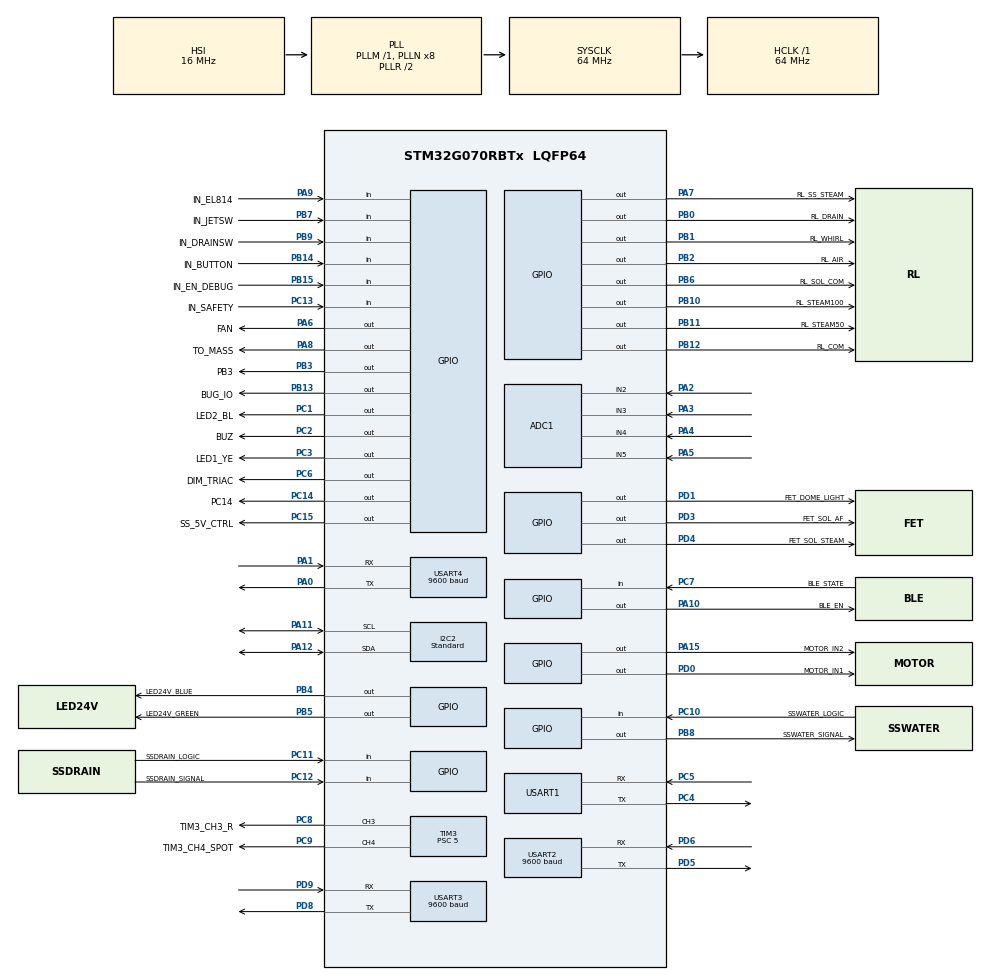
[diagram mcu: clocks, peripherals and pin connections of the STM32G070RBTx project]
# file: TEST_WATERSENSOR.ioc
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ADC1.Channel-0\#ChannelRegularConversion=ADC_CHANNEL_2
ADC1.Channel-1\#ChannelRegularConversion=ADC_CHANNEL_3
ADC1.Channel-2\#ChannelRegularConversion=ADC_CHANNEL_4
ADC1.Channel-3\#ChannelRegularConversion=ADC_CHANNEL_5
ADC1.ClockPrescaler=ADC_CLOCK_ASYNC_DIV4
ADC1.ContinuousConvMode=ENABLE
ADC1.DMAContinuousRequests=ENABLE
ADC1.NbrOfConversion=4
ADC1.NbrOfConversionFlag=1
ADC1.Rank-0\#ChannelRegularConversion=1
ADC1.Rank-1\#ChannelRegularConversion=2
ADC1.Rank-2\#ChannelRegularConversion=3
ADC1.Rank-3\#ChannelRegularConversion=4
ADC1.SamplingTime-0\#ChannelRegularConversion=ADC_SAMPLINGTIME_COMMON_1
ADC1.SamplingTime-1\#ChannelRegularConversion=ADC_SAMPLINGTIME_COMMON_1
ADC1.SamplingTime-2\#ChannelRegularConversion=ADC_SAMPLINGTIME_COMMON_1
ADC1.SamplingTime-3\#ChannelRegularConversion=ADC_SAMPLINGTIME_COMMON_1
ADC1.SamplingTimeCommon1=ADC_SAMPLETIME_160CYCLES_5
ADC1.SamplingTimeCommon2=ADC_SAMPLETIME_160CYCLES_5
ADC1.SelectedChannel=ADC_CHANNEL_2|ADC_CHANNEL_3|ADC_CHANNEL_4|ADC_CHANNEL_5
ADC1.master=1
Dma.ADC1.0.Direction=DMA_PERIPH_TO_MEMORY
Dma.ADC1.0.EventEnable=DISABLE
Dma.ADC1.0.Instance=DMA1_Channel1
Dma.ADC1.0.MemDataAlignment=DMA_MDATAALIGN_HALFWORD
Dma.ADC1.0.MemInc=DMA_MINC_ENABLE
Dma.ADC1.0.Mode=DMA_CIRCULAR
Dma.ADC1.0.PeriphDataAlignment=DMA_PDATAALIGN_HALFWORD
Dma.ADC1.0.PeriphInc=DMA_PINC_DISABLE
Dma.ADC1.0.Polarity=HAL_DMAMUX_REQ_GEN_RISING
Dma.ADC1.0.Priority=DMA_PRIORITY_LOW
Dma.ADC1.0.RequestNumber=1
Dma.ADC1.0.SignalID=NONE
Dma.ADC1.0.SyncEnable=DISABLE
Dma.ADC1.0.SyncPolarity=HAL_DMAMUX_SYNC_NO_EVENT
Dma.ADC1.0.SyncRequestNumber=1
Dma.ADC1.0.SyncSignalID=NONE
Dma.Request0=ADC1
I2C2.I2C_Speed_Mode=I2C_Standard
I2C2.Timing=0x10707DBC
IWDG.Prescaler=IWDG_PRESCALER_32
Mcu.Family=STM32G0
Mcu.Name=STM32G070RBTx
Mcu.Package=LQFP64
NVIC.ADC1_IRQn=true\:0\:0\:true\:false\:true\:true\:true\:true
NVIC.DMA1_Channel1_IRQn=true\:0\:0\:true\:false\:true\:false\:true\:true
NVIC.TIM6_IRQn=true\:1\:0\:true\:false\:true\:true\:true\:true
NVIC.TIM7_IRQn=true\:0\:0\:false\:false\:true\:true\:true\:true
NVIC.USART1_IRQn=true\:0\:0\:false\:false\:true\:true\:true\:true
NVIC.USART2_IRQn=true\:0\:0\:false\:false\:true\:true\:true\:true
NVIC.USART3_4_IRQn=true\:0\:0\:false\:false\:true\:true\:true\:true
PA0.Mode=Asynchronous
PA0.Signal=USART4_TX
PA1.Mode=Asynchronous
PA1.Signal=USART4_RX
PA10.GPIO_Label=BLE_EN
PA10.GPIO_PuPd=GPIO_PULLDOWN
PA10.Signal=GPIO_Output
PA11\ [PA9].GPIO_Pu=GPIO_PULLUP
PA11\ [PA9].Mode=I2C
PA11\ [PA9].Signal=I2C2_SCL
PA12\ [PA10].GPIO_Pu=GPIO_PULLUP
PA12\ [PA10].Mode=I2C
PA12\ [PA10].Signal=I2C2_SDA
PA13.Mode=Serial_Wire
PA13.Signal=SYS_SWDIO
PA14-BOOT0.Mode=Serial_Wire
PA14-BOOT0.Signal=SYS_SWCLK
PA15.GPIO_Label=MOTOR_IN2
PA15.Signal=GPIO_Output
PA2.Mode=IN2
PA2.Signal=ADC1_IN2
PA3.Mode=IN3
PA3.Signal=ADC1_IN3
PA4.Mode=IN4
PA4.Signal=ADC1_IN4
PA5.Mode=IN5
PA5.Signal=ADC1_IN5
PA6.GPIO_Label=FAN
PA6.GPIO_ModeDefaultOutputPP=GPIO_MODE_OUTPUT_PP
PA6.GPIO_PuPd=GPIO_PULLDOWN
PA6.PinState=GPIO_PIN_RESET
PA6.Signal=GPIO_Output
PA7.GPIO_Label=RL_SS_STEAM
PA7.GPIO_ModeDefaultOutputPP=GPIO_MODE_OUTPUT_PP
PA7.GPIO_PuPd=GPIO_PULLDOWN
PA7.GPIO_Speed=GPIO_SPEED_FREQ_LOW
PA7.PinState=GPIO_PIN_RESET
PA7.Signal=GPIO_Output
PA8.GPIO_Label=TO_MASS
PA8.GPIO_PuPd=GPIO_PULLDOWN
PA8.GPIO_Speed=GPIO_SPEED_FREQ_LOW
PA8.Signal=GPIO_Output
PA9.GPIO_Label=IN_EL814
PA9.GPIO_PuPd=GPIO_PULLUP
PA9.Signal=GPIO_Input
PB0.GPIO_Label=RL_DRAIN
PB0.GPIO_ModeDefaultOutputPP=GPIO_MODE_OUTPUT_PP
PB0.GPIO_PuPd=GPIO_PULLDOWN
PB0.GPIO_Speed=GPIO_SPEED_FREQ_LOW
PB0.PinState=GPIO_PIN_RESET
PB0.Signal=GPIO_Output
PB1.GPIO_Label=RL_WHIRL
PB1.GPIO_ModeDefaultOutputPP=GPIO_MODE_OUTPUT_PP
PB1.GPIO_PuPd=GPIO_PULLDOWN
PB1.GPIO_Speed=GPIO_SPEED_FREQ_LOW
PB1.PinState=GPIO_PIN_RESET
PB1.Signal=GPIO_Output
PB10.GPIO_Label=RL_STEAM100
PB10.GPIO_ModeDefaultOutputPP=GPIO_MODE_OUTPUT_PP
PB10.GPIO_PuPd=GPIO_PULLDOWN
PB10.GPIO_Speed=GPIO_SPEED_FREQ_LOW
PB10.PinState=GPIO_PIN_RESET
PB10.Signal=GPIO_Output
PB11.GPIO_Label=RL_STEAM50
PB11.GPIO_ModeDefaultOutputPP=GPIO_MODE_OUTPUT_PP
PB11.GPIO_PuPd=GPIO_PULLDOWN
PB11.GPIO_Speed=GPIO_SPEED_FREQ_LOW
PB11.PinState=GPIO_PIN_RESET
PB11.Signal=GPIO_Output
PB12.GPIO_Label=RL_COM
PB12.GPIO_ModeDefaultOutputPP=GPIO_MODE_OUTPUT_PP
PB12.GPIO_PuPd=GPIO_PULLDOWN
PB12.GPIO_Speed=GPIO_SPEED_FREQ_LOW
PB12.PinState=GPIO_PIN_RESET
PB12.Signal=GPIO_Output
PB13.GPIO_Label=BUG_IO
PB13.GPIO_ModeDefaultOutputPP=GPIO_MODE_OUTPUT_PP
PB13.GPIO_PuPd=GPIO_PULLUP
PB13.GPIO_Speed=GPIO_SPEED_FREQ_VERY_HIGH
PB13.PinState=GPIO_PIN_RESET
PB13.Signal=GPIO_Output
PB14.GPIO_Label=IN_BUTTON
PB14.GPIO_Mode=GPIO_MODE_INPUT
PB14.GPIO_PuPd=GPIO_PULLUP
PB14.Signal=GPIO_Input
PB15.GPIO_Label=IN_EN_DEBUG
PB15.GPIO_Mode=GPIO_MODE_INPUT
PB15.GPIO_PuPd=GPIO_PULLUP
PB15.Signal=GPIO_Input
PB2.GPIO_Label=RL_AIR
PB2.GPIO_ModeDefaultOutputPP=GPIO_MODE_OUTPUT_PP
PB2.GPIO_PuPd=GPIO_PULLDOWN
PB2.GPIO_Speed=GPIO_SPEED_FREQ_LOW
PB2.PinState=GPIO_PIN_RESET
PB2.Signal=GPIO_Output
PB3.GPIO_Label=PB3
PB3.Signal=GPIO_Output
PB4.GPIO_Label=LED24V_BLUE
PB4.GPIO_ModeDefaultOutputPP=GPIO_MODE_OUTPUT_PP
PB4.GPIO_PuPd=GPIO_PULLUP
PB4.PinState=GPIO_PIN_SET
PB4.Signal=GPIO_Output
PB5.GPIO_Label=LED24V_GREEN
PB5.GPIO_ModeDefaultOutputPP=GPIO_MODE_OUTPUT_PP
PB5.GPIO_PuPd=GPIO_PULLUP
PB5.PinState=GPIO_PIN_SET
PB5.Signal=GPIO_Output
PB6.GPIO_Label=RL_SOL_COM
PB6.GPIO_ModeDefaultOutputPP=GPIO_MODE_OUTPUT_PP
PB6.GPIO_PuPd=GPIO_PULLDOWN
PB6.GPIO_Speed=GPIO_SPEED_FREQ_LOW
PB6.PinState=GPIO_PIN_RESET
PB6.Signal=GPIO_Output
PB7.GPIO_Label=IN_JETSW
PB7.GPIO_Mode=GPIO_MODE_INPUT
PB7.GPIO_PuPd=GPIO_PULLUP
PB7.Signal=GPIO_Input
PB8.GPIO_Label=SSWATER_SIGNAL
PB8.GPIO_ModeDefaultOutputPP=GPIO_MODE_OUTPUT_PP
PB8.GPIO_PuPd=GPIO_PULLUP
PB8.PinState=GPIO_PIN_SET
PB8.Signal=GPIO_Output
PB9.GPIO_Label=IN_DRAINSW
PB9.GPIO_Mode=GPIO_MODE_INPUT
PB9.GPIO_PuPd=GPIO_PULLUP
PB9.Signal=GPIO_Input
PC1.GPIO_Label=LED2_BL
PC1.Signal=GPIO_Output
PC10.GPIO_Label=SSWATER_LOGIC
PC10.GPIO_Mode=GPIO_MODE_INPUT
PC10.GPIO_PuPd=GPIO_PULLUP
PC10.Signal=GPIO_Input
PC11.GPIO_Label=SSDRAIN_LOGIC
PC11.GPIO_Mode=GPIO_MODE_INPUT
PC11.GPIO_PuPd=GPIO_PULLUP
PC11.Signal=GPIO_Input
PC12.GPIO_Label=SSDRAIN_SIGNAL
PC12.GPIO_PuPd=GPIO_PULLUP
PC12.Signal=GPIO_Input
PC13.GPIO_Label=IN_SAFETY
PC13.GPIO_Mode=GPIO_MODE_INPUT
PC13.GPIO_PuPd=GPIO_PULLUP
PC13.Signal=GPIO_Input
PC14-OSC32_IN\ (PC14).GPIO_Label=PC14
PC14-OSC32_IN\ (PC14).Signal=GPIO_Output
PC15-OSC32_OUT\ (PC15).GPIO_Label=SS_5V_CTRL
PC15-OSC32_OUT\ (PC15).GPIO_ModeDefaultOutputPP=GPIO_MODE_OUTPUT_PP
PC15-OSC32_OUT\ (PC15).GPIO_PuPd=GPIO_PULLUP
PC15-OSC32_OUT\ (PC15).PinState=GPIO_PIN_SET
PC15-OSC32_OUT\ (PC15).Signal=GPIO_Output
PC2.GPIO_Label=BUZ
PC2.GPIO_PuPd=GPIO_PULLDOWN
PC2.Signal=GPIO_Output
PC3.GPIO_Label=LED1_YE
PC3.GPIO_PuPd=GPIO_NOPULL
PC3.Signal=GPIO_Output
PC4.Mode=Asynchronous
PC4.Signal=USART1_TX
PC5.Mode=Asynchronous
PC5.Signal=USART1_RX
PC6.GPIO_Label=DIM_TRIAC
PC6.GPIO_ModeDefaultOutputPP=GPIO_MODE_OUTPUT_PP
PC6.GPIO_PuPd=GPIO_PULLDOWN
PC6.GPIO_Speed=GPIO_SPEED_FREQ_HIGH
PC6.Signal=GPIO_Output
PC7.GPIO_Label=BLE_STATE
PC7.GPIO_PuPd=GPIO_PULLUP
PC7.Signal=GPIO_Input
PC8.GPIO_Label=TIM3_CH3_R
PC8.Signal=S_TIM3_CH3
PC9.GPIO_Label=TIM3_CH4_SPOT
PC9.Signal=S_TIM3_CH4
PD0.GPIO_Label=MOTOR_IN1
PD0.Signal=GPIO_Output
PD1.GPIO_Label=FET_DOME_LIGHT
PD1.GPIO_ModeDefaultOutputPP=GPIO_MODE_OUTPUT_PP
PD1.GPIO_PuPd=GPIO_PULLUP
PD1.GPIO_Speed=GPIO_SPEED_FREQ_LOW
PD1.PinState=GPIO_PIN_SET
PD1.Signal=GPIO_Output
PD3.GPIO_Label=FET_SOL_AF
PD3.GPIO_ModeDefaultOutputPP=GPIO_MODE_OUTPUT_PP
PD3.GPIO_PuPd=GPIO_PULLUP
PD3.GPIO_Speed=GPIO_SPEED_FREQ_LOW
PD3.PinState=GPIO_PIN_SET
PD3.Signal=GPIO_Output
PD4.GPIO_Label=FET_SOL_STEAM
PD4.GPIO_ModeDefaultOutputPP=GPIO_MODE_OUTPUT_PP
PD4.GPIO_PuPd=GPIO_PULLUP
PD4.GPIO_Speed=GPIO_SPEED_FREQ_LOW
PD4.PinState=GPIO_PIN_SET
PD4.Signal=GPIO_Output
PD5.Mode=Asynchronous
PD5.Signal=USART2_TX
PD6.Mode=Asynchronous
PD6.Signal=USART2_RX
PD8.Mode=Asynchronous
PD8.Signal=USART3_TX
PD9.Mode=Asynchronous
PD9.Signal=USART3_RX
ProjectManager.HeapSize=0x200
ProjectManager.StackSize=0x400
ProjectManager.TargetToolchain=STM32CubeIDE
RCC.ADCFreq_Value=64000000
RCC.AHBFreq_Value=64000000
RCC.CortexFreq_Value=64000000
RCC.EXTERNAL_CLOCK_VALUE=48000
RCC.HCLKFreq_Value=64000000
RCC.HSE_VALUE=8000000
RCC.HSI_VALUE=16000000
RCC.LSE_VALUE=32768
RCC.SYSCLKFreq_VALUE=64000000
RCC.SYSCLKSource=RCC_SYSCLKSOURCE_PLLCLK
RCC.VCOOutputFreq_Value=128000000
SH.S_TIM3_CH3.0=TIM3_CH3,PWM Generation3 CH3
SH.S_TIM3_CH4.0=TIM3_CH4,PWM Generation4 CH4
TIM3.AutoReloadPreload=TIM_AUTORELOAD_PRELOAD_ENABLE
TIM3.Channel-PWM\ Generation3\ CH3=TIM_CHANNEL_3
TIM3.Channel-PWM\ Generation4\ CH4=TIM_CHANNEL_4
TIM3.OC3Preload_PWM=DISABLE
TIM3.OCFastMode_PWM-PWM\ Generation3\ CH3=TIM_OCFAST_ENABLE
TIM3.OCPolarity_3=TIM_OCPOLARITY_LOW
TIM3.OCPolarity_4=TIM_OCPOLARITY_LOW
TIM3.Period=38000
TIM3.Prescaler=5
TIM3.Pulse-PWM\ Generation3\ CH3=0
TIM6.Period=104
TIM6.Prescaler=64
TIM7.AutoReloadPreload=TIM_AUTORELOAD_PRELOAD_ENABLE
TIM7.Period=999
TIM7.Prescaler=64
USART1.VirtualMode-Asynchronous=VM_ASYNC
USART2.BaudRate=9600
USART2.VirtualMode-Asynchronous=VM_ASYNC
USART3.BaudRate=9600
USART3.OneBitSampling=UART_ONE_BIT_SAMPLE_DISABLE
USART3.VirtualMode-Asynchronous=VM_ASYNC
USART4.BaudRate=9600
USART4.VirtualMode-Asynchronous=VM_ASYNC
VP_IWDG_VS_IWDG.Mode=IWDG_Activate
VP_SYS_VS_DBSignals.Mode=DisableDeadBatterySignals
VP_TIM3_VS_ClockSourceINT.Mode=Internal
VP_TIM6_VS_ClockSourceINT.Mode=Enable_Timer
VP_TIM7_VS_ClockSourceINT.Mode=Enable_Timer
board=custom

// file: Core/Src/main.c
/* USER CODE BEGIN Header */
/**
  ******************************************************************************
  * @file           : main.c
  * @brief          : Main program body
  ******************************************************************************
  * @attention
  *
  * Copyright (c) 2023 STMicroelectronics.
  * All rights reserved.
  *
  * This software is licensed under terms that can be found in the LICENSE file
  * in the root directory of this software component.
  * If no LICENSE file comes with this software, it is provided AS-IS.
  *
  ******************************************************************************
  */
/* USER CODE END Header */
#include "main.h"

/* USER CODE BEGIN Includes */
#include "myHeader.h"
/* USER CODE END Includes */

ADC_HandleTypeDef hadc1;
DMA_HandleTypeDef hdma_adc1;

I2C_HandleTypeDef hi2c2;

IWDG_HandleTypeDef hiwdg;

TIM_HandleTypeDef htim3;
TIM_HandleTypeDef htim6;
TIM_HandleTypeDef htim7;

UART_HandleTypeDef huart1;
UART_HandleTypeDef huart2;
UART_HandleTypeDef huart3;
UART_HandleTypeDef huart4;

void SystemClock_Config(void);
static void MX_GPIO_Init(void);
static void MX_DMA_Init(void);
static void MX_ADC1_Init(void);
static void MX_TIM3_Init(void);
static void MX_TIM6_Init(void);
static void MX_USART2_UART_Init(void);
static void MX_USART3_UART_Init(void);
static void MX_USART4_UART_Init(void);
static void MX_IWDG_Init(void);
static void MX_USART1_UART_Init(void);
static void MX_I2C2_Init(void);
static void MX_TIM7_Init(void);

int main(void)
{

  /* MCU Configuration--------------------------------------------------------*/

  /* Reset of all peripherals, Initializes the Flash interface and the Systick. */
  HAL_Init();

  /* Configure the system clock */
  SystemClock_Config();

  /* Initialize all configured peripherals */
  MX_GPIO_Init();
  MX_DMA_Init();
  MX_ADC1_Init();
  MX_TIM3_Init();
  MX_TIM6_Init();
  MX_USART2_UART_Init();
  MX_USART3_UART_Init();
  MX_USART4_UART_Init();
  MX_IWDG_Init();
  MX_USART1_UART_Init();
  MX_I2C2_Init();
  MX_TIM7_Init();
  /* USER CODE BEGIN 2 */

  testWaterSensorInit();

  /* USER CODE END 2 */

  /* Infinite loop */
  /* USER CODE BEGIN WHILE */
  HAL_IWDG_Init(&hiwdg);
  while (1)
  {
      HAL_IWDG_Refresh(&hiwdg);
    /* USER CODE END WHILE */

    /* USER CODE BEGIN 3 */
      testWaterSensorLoop();
  }
  /* USER CODE END 3 */
}

void SystemClock_Config(void)
{
  RCC_OscInitTypeDef RCC_OscInitStruct = {0};
  RCC_ClkInitTypeDef RCC_ClkInitStruct = {0};

  /** Configure the main internal regulator output voltage
  */
  HAL_PWREx_ControlVoltageScaling(PWR_REGULATOR_VOLTAGE_SCALE1);

  /** Initializes the RCC Oscillators according to the specified parameters
  * in the RCC_OscInitTypeDef structure.
  */
  RCC_OscInitStruct.OscillatorType = RCC_OSCILLATORTYPE_HSI|RCC_OSCILLATORTYPE_LSI;
  RCC_OscInitStruct.HSIState = RCC_HSI_ON;
  RCC_OscInitStruct.HSIDiv = RCC_HSI_DIV1;
  RCC_OscInitStruct.HSICalibrationValue = RCC_HSICALIBRATION_DEFAULT;
  RCC_OscInitStruct.LSIState = RCC_LSI_ON;
  RCC_OscInitStruct.PLL.PLLState = RCC_PLL_ON;
  RCC_OscInitStruct.PLL.PLLSource = RCC_PLLSOURCE_HSI;
  RCC_OscInitStruct.PLL.PLLM = RCC_PLLM_DIV1;
  RCC_OscInitStruct.PLL.PLLN = 8;
  RCC_OscInitStruct.PLL.PLLP = RCC_PLLP_DIV2;
  RCC_OscInitStruct.PLL.PLLR = RCC_PLLR_DIV2;
  if (HAL_RCC_OscConfig(&RCC_OscInitStruct) != HAL_OK)
  {
    Error_Handler();
  }

  /** Initializes the CPU, AHB and APB buses clocks
  */
  RCC_ClkInitStruct.ClockType = RCC_CLOCKTYPE_HCLK|RCC_CLOCKTYPE_SYSCLK
                              |RCC_CLOCKTYPE_PCLK1;
  RCC_ClkInitStruct.SYSCLKSource = RCC_SYSCLKSOURCE_PLLCLK;
  RCC_ClkInitStruct.AHBCLKDivider = RCC_SYSCLK_DIV1;
  RCC_ClkInitStruct.APB1CLKDivider = RCC_HCLK_DIV1;

  if (HAL_RCC_ClockConfig(&RCC_ClkInitStruct, FLASH_LATENCY_2) != HAL_OK)
  {
    Error_Handler();
  }
}

static void MX_ADC1_Init(void)
{

  ADC_ChannelConfTypeDef sConfig = {0};

  /** Configure the global features of the ADC (Clock, Resolution, Data Alignment and number of conversion)
  */
  hadc1.Instance = ADC1;
  hadc1.Init.ClockPrescaler = ADC_CLOCK_ASYNC_DIV4;
  hadc1.Init.Resolution = ADC_RESOLUTION_12B;
  hadc1.Init.DataAlign = ADC_DATAALIGN_RIGHT;
  hadc1.Init.ScanConvMode = ADC_SCAN_ENABLE;
  hadc1.Init.EOCSelection = ADC_EOC_SINGLE_CONV;
  hadc1.Init.LowPowerAutoWait = DISABLE;
  hadc1.Init.LowPowerAutoPowerOff = DISABLE;
  hadc1.Init.ContinuousConvMode = ENABLE;
  hadc1.Init.NbrOfConversion = 4;
  hadc1.Init.ExternalTrigConv = ADC_SOFTWARE_START;
  hadc1.Init.ExternalTrigConvEdge = ADC_EXTERNALTRIGCONVEDGE_NONE;
  hadc1.Init.DMAContinuousRequests = ENABLE;
  hadc1.Init.Overrun = ADC_OVR_DATA_PRESERVED;
  hadc1.Init.SamplingTimeCommon1 = ADC_SAMPLETIME_160CYCLES_5;
  hadc1.Init.SamplingTimeCommon2 = ADC_SAMPLETIME_160CYCLES_5;
  hadc1.Init.OversamplingMode = DISABLE;
  hadc1.Init.TriggerFrequencyMode = ADC_TRIGGER_FREQ_HIGH;
  if (HAL_ADC_Init(&hadc1) != HAL_OK)
  {
    Error_Handler();
  }

  /** Configure Regular Channel
  */
  sConfig.Channel = ADC_CHANNEL_2;
  sConfig.Rank = ADC_REGULAR_RANK_1;
  sConfig.SamplingTime = ADC_SAMPLINGTIME_COMMON_1;
  if (HAL_ADC_ConfigChannel(&hadc1, &sConfig) != HAL_OK)
  {
    Error_Handler();
  }

  /** Configure Regular Channel
  */
  sConfig.Channel = ADC_CHANNEL_3;
  sConfig.Rank = ADC_REGULAR_RANK_2;
  if (HAL_ADC_ConfigChannel(&hadc1, &sConfig) != HAL_OK)
  {
    Error_Handler();
  }

  /** Configure Regular Channel
  */
  sConfig.Channel = ADC_CHANNEL_4;
  sConfig.Rank = ADC_REGULAR_RANK_3;
  if (HAL_ADC_ConfigChannel(&hadc1, &sConfig) != HAL_OK)
  {
    Error_Handler();
  }

  /** Configure Regular Channel
  */
  sConfig.Channel = ADC_CHANNEL_5;
  sConfig.Rank = ADC_REGULAR_RANK_4;
  if (HAL_ADC_ConfigChannel(&hadc1, &sConfig) != HAL_OK)
  {
    Error_Handler();
  }

}

static void MX_I2C2_Init(void)
{

  hi2c2.Instance = I2C2;
  hi2c2.Init.Timing = 0x10707DBC;
  hi2c2.Init.OwnAddress1 = 0;
  hi2c2.Init.AddressingMode = I2C_ADDRESSINGMODE_7BIT;
  hi2c2.Init.DualAddressMode = I2C_DUALADDRESS_DISABLE;
  hi2c2.Init.OwnAddress2 = 0;
  hi2c2.Init.OwnAddress2Masks = I2C_OA2_NOMASK;
  hi2c2.Init.GeneralCallMode = I2C_GENERALCALL_DISABLE;
  hi2c2.Init.NoStretchMode = I2C_NOSTRETCH_DISABLE;
  if (HAL_I2C_Init(&hi2c2) != HAL_OK)
  {
    Error_Handler();
  }

  /** Configure Analogue filter
  */
  if (HAL_I2CEx_ConfigAnalogFilter(&hi2c2, I2C_ANALOGFILTER_ENABLE) != HAL_OK)
  {
    Error_Handler();
  }

  /** Configure Digital filter
  */
  if (HAL_I2CEx_ConfigDigitalFilter(&hi2c2, 0) != HAL_OK)
  {
    Error_Handler();
  }

}

static void MX_IWDG_Init(void)
{

  hiwdg.Instance = IWDG;
  hiwdg.Init.Prescaler = IWDG_PRESCALER_32;
  hiwdg.Init.Window = 4095;
  hiwdg.Init.Reload = 4095;
  if (HAL_IWDG_Init(&hiwdg) != HAL_OK)
  {
    Error_Handler();
  }

}

static void MX_TIM3_Init(void)
{

  TIM_ClockConfigTypeDef sClockSourceConfig = {0};
  TIM_MasterConfigTypeDef sMasterConfig = {0};
  TIM_OC_InitTypeDef sConfigOC = {0};

  htim3.Instance = TIM3;
  htim3.Init.Prescaler = 5;
  htim3.Init.CounterMode = TIM_COUNTERMODE_UP;
  htim3.Init.Period = 38000;
  htim3.Init.ClockDivision = TIM_CLOCKDIVISION_DIV1;
  htim3.Init.AutoReloadPreload = TIM_AUTORELOAD_PRELOAD_ENABLE;
  if (HAL_TIM_Base_Init(&htim3) != HAL_OK)
  {
    Error_Handler();
  }
  sClockSourceConfig.ClockSource = TIM_CLOCKSOURCE_INTERNAL;
  if (HAL_TIM_ConfigClockSource(&htim3, &sClockSourceConfig) != HAL_OK)
  {
    Error_Handler();
  }
  if (HAL_TIM_PWM_Init(&htim3) != HAL_OK)
  {
    Error_Handler();
  }
  sMasterConfig.MasterOutputTrigger = TIM_TRGO_RESET;
  sMasterConfig.MasterSlaveMode = TIM_MASTERSLAVEMODE_DISABLE;
  if (HAL_TIMEx_MasterConfigSynchronization(&htim3, &sMasterConfig) != HAL_OK)
  {
    Error_Handler();
  }
  sConfigOC.OCMode = TIM_OCMODE_PWM1;
  sConfigOC.Pulse = 0;
  sConfigOC.OCPolarity = TIM_OCPOLARITY_LOW;
  sConfigOC.OCFastMode = TIM_OCFAST_ENABLE;
  if (HAL_TIM_PWM_ConfigChannel(&htim3, &sConfigOC, TIM_CHANNEL_3) != HAL_OK)
  {
    Error_Handler();
  }
  __HAL_TIM_DISABLE_OCxPRELOAD(&htim3, TIM_CHANNEL_3);
  sConfigOC.OCFastMode = TIM_OCFAST_DISABLE;
  if (HAL_TIM_PWM_ConfigChannel(&htim3, &sConfigOC, TIM_CHANNEL_4) != HAL_OK)
  {
    Error_Handler();
  }
  HAL_TIM_MspPostInit(&htim3);

}

static void MX_TIM6_Init(void)
{

  TIM_MasterConfigTypeDef sMasterConfig = {0};

  htim6.Instance = TIM6;
  htim6.Init.Prescaler = 64;
  htim6.Init.CounterMode = TIM_COUNTERMODE_UP;
  htim6.Init.Period = 104;
  htim6.Init.AutoReloadPreload = TIM_AUTORELOAD_PRELOAD_DISABLE;
  if (HAL_TIM_Base_Init(&htim6) != HAL_OK)
  {
    Error_Handler();
  }
  sMasterConfig.MasterOutputTrigger = TIM_TRGO_RESET;
  sMasterConfig.MasterSlaveMode = TIM_MASTERSLAVEMODE_DISABLE;
  if (HAL_TIMEx_MasterConfigSynchronization(&htim6, &sMasterConfig) != HAL_OK)
  {
    Error_Handler();
  }

}

static void MX_TIM7_Init(void)
{

  TIM_MasterConfigTypeDef sMasterConfig = {0};

  htim7.Instance = TIM7;
  htim7.Init.Prescaler = 64;
  htim7.Init.CounterMode = TIM_COUNTERMODE_UP;
  htim7.Init.Period = 999;
  htim7.Init.AutoReloadPreload = TIM_AUTORELOAD_PRELOAD_ENABLE;
  if (HAL_TIM_Base_Init(&htim7) != HAL_OK)
  {
    Error_Handler();
  }
  sMasterConfig.MasterOutputTrigger = TIM_TRGO_RESET;
  sMasterConfig.MasterSlaveMode = TIM_MASTERSLAVEMODE_DISABLE;
  if (HAL_TIMEx_MasterConfigSynchronization(&htim7, &sMasterConfig) != HAL_OK)
  {
    Error_Handler();
  }

}

static void MX_USART1_UART_Init(void)
{

  huart1.Instance = USART1;
  huart1.Init.BaudRate = 115200;
  huart1.Init.WordLength = UART_WORDLENGTH_8B;
  huart1.Init.StopBits = UART_STOPBITS_1;
  huart1.Init.Parity = UART_PARITY_NONE;
  huart1.Init.Mode = UART_MODE_TX_RX;
  huart1.Init.HwFlowCtl = UART_HWCONTROL_NONE;
  huart1.Init.OverSampling = UART_OVERSAMPLING_16;
  huart1.Init.OneBitSampling = UART_ONE_BIT_SAMPLE_DISABLE;
  huart1.Init.ClockPrescaler = UART_PRESCALER_DIV1;
  huart1.AdvancedInit.AdvFeatureInit = UART_ADVFEATURE_NO_INIT;
  if (HAL_UART_Init(&huart1) != HAL_OK)
  {
    Error_Handler();
  }
  if (HAL_UARTEx_SetTxFifoThreshold(&huart1, UART_TXFIFO_THRESHOLD_1_8) != HAL_OK)
  {
    Error_Handler();
  }
  if (HAL_UARTEx_SetRxFifoThreshold(&huart1, UART_RXFIFO_THRESHOLD_1_8) != HAL_OK)
  {
    Error_Handler();
  }
  if (HAL_UARTEx_DisableFifoMode(&huart1) != HAL_OK)
  {
    Error_Handler();
  }

}

static void MX_USART2_UART_Init(void)
{

  huart2.Instance = USART2;
  huart2.Init.BaudRate = 9600;
  huart2.Init.WordLength = UART_WORDLENGTH_8B;
  huart2.Init.StopBits = UART_STOPBITS_1;
  huart2.Init.Parity = UART_PARITY_NONE;
  huart2.Init.Mode = UART_MODE_TX_RX;
  huart2.Init.HwFlowCtl = UART_HWCONTROL_NONE;
  huart2.Init.OverSampling = UART_OVERSAMPLING_16;
  huart2.Init.OneBitSampling = UART_ONE_BIT_SAMPLE_DISABLE;
  huart2.Init.ClockPrescaler = UART_PRESCALER_DIV1;
  huart2.AdvancedInit.AdvFeatureInit = UART_ADVFEATURE_NO_INIT;
  if (HAL_UART_Init(&huart2) != HAL_OK)
  {
    Error_Handler();
  }
  if (HAL_UARTEx_SetTxFifoThreshold(&huart2, UART_TXFIFO_THRESHOLD_1_8) != HAL_OK)
  {
    Error_Handler();
  }
  if (HAL_UARTEx_SetRxFifoThreshold(&huart2, UART_RXFIFO_THRESHOLD_1_8) != HAL_OK)
  {
    Error_Handler();
  }
  if (HAL_UARTEx_DisableFifoMode(&huart2) != HAL_OK)
  {
    Error_Handler();
  }

}

static void MX_USART3_UART_Init(void)
{

  huart3.Instance = USART3;
  huart3.Init.BaudRate = 9600;
  huart3.Init.WordLength = UART_WORDLENGTH_8B;
  huart3.Init.StopBits = UART_STOPBITS_1;
  huart3.Init.Parity = UART_PARITY_NONE;
  huart3.Init.Mode = UART_MODE_TX_RX;
  huart3.Init.HwFlowCtl = UART_HWCONTROL_NONE;
  huart3.Init.OverSampling = UART_OVERSAMPLING_16;
  huart3.Init.OneBitSampling = UART_ONE_BIT_SAMPLE_DISABLE;
  huart3.Init.ClockPrescaler = UART_PRESCALER_DIV1;
  huart3.AdvancedInit.AdvFeatureInit = UART_ADVFEATURE_NO_INIT;
  if (HAL_UART_Init(&huart3) != HAL_OK)
  {
    Error_Handler();
  }

}

static void MX_USART4_UART_Init(void)
{

  huart4.Instance = USART4;
  huart4.Init.BaudRate = 9600;
  huart4.Init.WordLength = UART_WORDLENGTH_8B;
  huart4.Init.StopBits = UART_STOPBITS_1;
  huart4.Init.Parity = UART_PARITY_NONE;
  huart4.Init.Mode = UART_MODE_TX_RX;
  huart4.Init.HwFlowCtl = UART_HWCONTROL_NONE;
  huart4.Init.OverSampling = UART_OVERSAMPLING_16;
  huart4.Init.OneBitSampling = UART_ONE_BIT_SAMPLE_DISABLE;
  huart4.Init.ClockPrescaler = UART_PRESCALER_DIV1;
  huart4.AdvancedInit.AdvFeatureInit = UART_ADVFEATURE_NO_INIT;
  if (HAL_UART_Init(&huart4) != HAL_OK)
  {
    Error_Handler();
  }

}

static void MX_DMA_Init(void)
{

  /* DMA controller clock enable */
  __HAL_RCC_DMA1_CLK_ENABLE();

  /* DMA interrupt init */
  /* DMA1_Channel1_IRQn interrupt configuration */
  HAL_NVIC_SetPriority(DMA1_Channel1_IRQn, 0, 0);
  HAL_NVIC_EnableIRQ(DMA1_Channel1_IRQn);

}

static void MX_GPIO_Init(void)
{
  GPIO_InitTypeDef GPIO_InitStruct = {0};

  /* GPIO Ports Clock Enable */
  __HAL_RCC_GPIOC_CLK_ENABLE();
  __HAL_RCC_GPIOA_CLK_ENABLE();
  __HAL_RCC_GPIOB_CLK_ENABLE();
  __HAL_RCC_GPIOD_CLK_ENABLE();

  /*Configure GPIO pin Output Level */
  HAL_GPIO_WritePin(GPIOC, PC14_Pin|LED2_BL_Pin|BUZ_Pin|LED1_YE_Pin
                          |DIM_TRIAC_Pin, GPIO_PIN_RESET);

  /*Configure GPIO pin Output Level */
  HAL_GPIO_WritePin(SS_5V_CTRL_GPIO_Port, SS_5V_CTRL_Pin, GPIO_PIN_SET);

  /*Configure GPIO pin Output Level */
  HAL_GPIO_WritePin(GPIOA, FAN_Pin|RL_SS_STEAM_Pin|TO_MASS_Pin|BLE_EN_Pin
                          |MOTOR_IN2_Pin, GPIO_PIN_RESET);

  /*Configure GPIO pin Output Level */
  HAL_GPIO_WritePin(GPIOB, RL_DRAIN_Pin|RL_WHIRL_Pin|RL_AIR_Pin|RL_STEAM100_Pin
                          |RL_STEAM50_Pin|RL_COM_Pin|BUG_IO_Pin|PB3_Pin
                          |RL_SOL_COM_Pin, GPIO_PIN_RESET);

  /*Configure GPIO pin Output Level */
  HAL_GPIO_WritePin(MOTOR_IN1_GPIO_Port, MOTOR_IN1_Pin, GPIO_PIN_RESET);

  /*Configure GPIO pin Output Level */
  HAL_GPIO_WritePin(GPIOD, FET_DOME_LIGHT_Pin|FET_SOL_AF_Pin|FET_SOL_STEAM_Pin, GPIO_PIN_SET);

  /*Configure GPIO pin Output Level */
  HAL_GPIO_WritePin(GPIOB, LED24V_BLUE_Pin|LED24V_GREEN_Pin|SSWATER_SIGNAL_Pin, GPIO_PIN_SET);

  /*Configure GPIO pins : SSDRAIN_LOGIC_Pin SSDRAIN_SIGNAL_Pin IN_SAFETY_Pin BLE_STATE_Pin
                           SSWATER_LOGIC_Pin */
  GPIO_InitStruct.Pin = SSDRAIN_LOGIC_Pin|SSDRAIN_SIGNAL_Pin|IN_SAFETY_Pin|BLE_STATE_Pin
                          |SSWATER_LOGIC_Pin;
  GPIO_InitStruct.Mode = GPIO_MODE_INPUT;
  GPIO_InitStruct.Pull = GPIO_PULLUP;
  HAL_GPIO_Init(GPIOC, &GPIO_InitStruct);

  /*Configure GPIO pins : PC14_Pin LED2_BL_Pin LED1_YE_Pin */
  GPIO_InitStruct.Pin = PC14_Pin|LED2_BL_Pin|LED1_YE_Pin;
  GPIO_InitStruct.Mode = GPIO_MODE_OUTPUT_PP;
  GPIO_InitStruct.Pull = GPIO_NOPULL;
  GPIO_InitStruct.Speed = GPIO_SPEED_FREQ_LOW;
  HAL_GPIO_Init(GPIOC, &GPIO_InitStruct);

  /*Configure GPIO pin : SS_5V_CTRL_Pin */
  GPIO_InitStruct.Pin = SS_5V_CTRL_Pin;
  GPIO_InitStruct.Mode = GPIO_MODE_OUTPUT_PP;
  GPIO_InitStruct.Pull = GPIO_PULLUP;
  GPIO_InitStruct.Speed = GPIO_SPEED_FREQ_LOW;
  HAL_GPIO_Init(SS_5V_CTRL_GPIO_Port, &GPIO_InitStruct);

  /*Configure GPIO pin : BUZ_Pin */
  GPIO_InitStruct.Pin = BUZ_Pin;
  GPIO_InitStruct.Mode = GPIO_MODE_OUTPUT_PP;
  GPIO_InitStruct.Pull = GPIO_PULLDOWN;
  GPIO_InitStruct.Speed = GPIO_SPEED_FREQ_LOW;
  HAL_GPIO_Init(BUZ_GPIO_Port, &GPIO_InitStruct);

  /*Configure GPIO pins : FAN_Pin RL_SS_STEAM_Pin TO_MASS_Pin BLE_EN_Pin */
  GPIO_InitStruct.Pin = FAN_Pin|RL_SS_STEAM_Pin|TO_MASS_Pin|BLE_EN_Pin;
  GPIO_InitStruct.Mode = GPIO_MODE_OUTPUT_PP;
  GPIO_InitStruct.Pull = GPIO_PULLDOWN;
  GPIO_InitStruct.Speed = GPIO_SPEED_FREQ_LOW;
  HAL_GPIO_Init(GPIOA, &GPIO_InitStruct);

  /*Configure GPIO pins : RL_DRAIN_Pin RL_WHIRL_Pin RL_AIR_Pin RL_STEAM100_Pin
                           RL_STEAM50_Pin RL_COM_Pin RL_SOL_COM_Pin */
  GPIO_InitStruct.Pin = RL_DRAIN_Pin|RL_WHIRL_Pin|RL_AIR_Pin|RL_STEAM100_Pin
                          |RL_STEAM50_Pin|RL_COM_Pin|RL_SOL_COM_Pin;
  GPIO_InitStruct.Mode = GPIO_MODE_OUTPUT_PP;
  GPIO_InitStruct.Pull = GPIO_PULLDOWN;
  GPIO_InitStruct.Speed = GPIO_SPEED_FREQ_LOW;
  HAL_GPIO_Init(GPIOB, &GPIO_InitStruct);

  /*Configure GPIO pin : BUG_IO_Pin */
  GPIO_InitStruct.Pin = BUG_IO_Pin;
  GPIO_InitStruct.Mode = GPIO_MODE_OUTPUT_PP;
  GPIO_InitStruct.Pull = GPIO_PULLUP;
  GPIO_InitStruct.Speed = GPIO_SPEED_FREQ_VERY_HIGH;
  HAL_GPIO_Init(BUG_IO_GPIO_Port, &GPIO_InitStruct);

  /*Configure GPIO pins : IN_BUTTON_Pin IN_EN_DEBUG_Pin IN_JETSW_Pin IN_DRAINSW_Pin */
  GPIO_InitStruct.Pin = IN_BUTTON_Pin|IN_EN_DEBUG_Pin|IN_JETSW_Pin|IN_DRAINSW_Pin;
  GPIO_InitStruct.Mode = GPIO_MODE_INPUT;
  GPIO_InitStruct.Pull = GPIO_PULLUP;
  HAL_GPIO_Init(GPIOB, &GPIO_InitStruct);

  /*Configure GPIO pin : IN_EL814_Pin */
  GPIO_InitStruct.Pin = IN_EL814_Pin;
  GPIO_InitStruct.Mode = GPIO_MODE_INPUT;
  GPIO_InitStruct.Pull = GPIO_PULLUP;
  HAL_GPIO_Init(IN_EL814_GPIO_Port, &GPIO_InitStruct);

  /*Configure GPIO pin : DIM_TRIAC_Pin */
  GPIO_InitStruct.Pin = DIM_TRIAC_Pin;
  GPIO_InitStruct.Mode = GPIO_MODE_OUTPUT_PP;
  GPIO_InitStruct.Pull = GPIO_PULLDOWN;
  GPIO_InitStruct.Speed = GPIO_SPEED_FREQ_HIGH;
  HAL_GPIO_Init(DIM_TRIAC_GPIO_Port, &GPIO_InitStruct);

  /*Configure GPIO pin : MOTOR_IN2_Pin */
  GPIO_InitStruct.Pin = MOTOR_IN2_Pin;
  GPIO_InitStruct.Mode = GPIO_MODE_OUTPUT_PP;
  GPIO_InitStruct.Pull = GPIO_NOPULL;
  GPIO_InitStruct.Speed = GPIO_SPEED_FREQ_LOW;
  HAL_GPIO_Init(MOTOR_IN2_GPIO_Port, &GPIO_InitStruct);

  /*Configure GPIO pin : MOTOR_IN1_Pin */
  GPIO_InitStruct.Pin = MOTOR_IN1_Pin;
  GPIO_InitStruct.Mode = GPIO_MODE_OUTPUT_PP;
  GPIO_InitStruct.Pull = GPIO_NOPULL;
  GPIO_InitStruct.Speed = GPIO_SPEED_FREQ_LOW;
  HAL_GPIO_Init(MOTOR_IN1_GPIO_Port, &GPIO_InitStruct);

  /*Configure GPIO pins : FET_DOME_LIGHT_Pin FET_SOL_AF_Pin FET_SOL_STEAM_Pin */
  GPIO_InitStruct.Pin = FET_DOME_LIGHT_Pin|FET_SOL_AF_Pin|FET_SOL_STEAM_Pin;
  GPIO_InitStruct.Mode = GPIO_MODE_OUTPUT_PP;
  GPIO_InitStruct.Pull = GPIO_PULLUP;
  GPIO_InitStruct.Speed = GPIO_SPEED_FREQ_LOW;
  HAL_GPIO_Init(GPIOD, &GPIO_InitStruct);

  /*Configure GPIO pin : PB3_Pin */
  GPIO_InitStruct.Pin = PB3_Pin;
  GPIO_InitStruct.Mode = GPIO_MODE_OUTPUT_PP;
  GPIO_InitStruct.Pull = GPIO_NOPULL;
  GPIO_InitStruct.Speed = GPIO_SPEED_FREQ_LOW;
  HAL_GPIO_Init(PB3_GPIO_Port, &GPIO_InitStruct);

  /*Configure GPIO pins : LED24V_BLUE_Pin LED24V_GREEN_Pin SSWATER_SIGNAL_Pin */
  GPIO_InitStruct.Pin = LED24V_BLUE_Pin|LED24V_GREEN_Pin|SSWATER_SIGNAL_Pin;
  GPIO_InitStruct.Mode = GPIO_MODE_OUTPUT_PP;
  GPIO_InitStruct.Pull = GPIO_PULLUP;
  GPIO_InitStruct.Speed = GPIO_SPEED_FREQ_LOW;
  HAL_GPIO_Init(GPIOB, &GPIO_InitStruct);

}

void Error_Handler(void)
{
  __disable_irq();
  while (1)
  {
  }
}
